# bao1x_peri register map
Vendor: baochip
Registers are 32-bit, read-write, reset 0x0 unless marked. A register's access mark holds for its fields unless they carry their own. Offsets are from the block's base; [hi:lo] are bit positions; {n}, {i} and the like mark numbered series; <NAME> marks a mode.

## UDMA_SPIS_0
Base 0x50112000
Same registers: UDMA_SPIS_1 0x50113000
0x00 REG_RX_SADDR — See `udma_spis_reg.sv <https://github.com/baochip/baochip-1x/blob/main/rtl/modul es/ifsub/rtl/udma_spis_reg.sv>`__
  [11:0] r_rx_startaddr
0x04 REG_RX_SIZE — See `udma_spis_reg.sv <https://github.com/baochip/baochip-1x/blob/main/rtl/modul es/ifsub/rtl/udma_spis_reg.sv>`__
  [15:0] r_rx_size
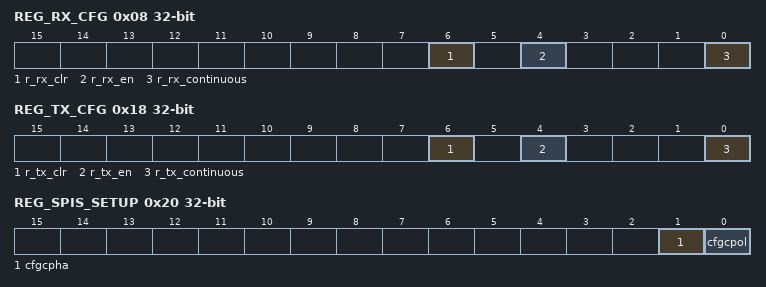
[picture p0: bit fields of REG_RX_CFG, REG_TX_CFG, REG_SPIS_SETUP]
0x08 REG_RX_CFG — See `udma_spis_reg.sv <https://github.com/baochip/baochip-1x/blob/main/rtl/modul es/ifsub/rtl/udma_spis_reg.sv>`__
  [6] r_rx_clr, [4] r_rx_en, [0] r_rx_continuous
0x10 REG_TX_SADDR — See `udma_spis_reg.sv <https://github.com/baochip/baochip-1x/blob/main/rtl/modul es/ifsub/rtl/udma_spis_reg.sv>`__
  [11:0] r_tx_startaddr
0x14 REG_TX_SIZE — See `udma_spis_reg.sv <https://github.com/baochip/baochip-1x/blob/main/rtl/modul es/ifsub/rtl/udma_spis_reg.sv>`__
  [15:0] r_tx_size
0x18 REG_TX_CFG — See `udma_spis_reg.sv <https://github.com/baochip/baochip-1x/blob/main/rtl/modul es/ifsub/rtl/udma_spis_reg.sv>`__
  [6] r_tx_clr, [4] r_tx_en, [0] r_tx_continuous
0x20 REG_SPIS_SETUP — See `udma_spis_reg.sv <https://github.com/baochip/baochip-1x/blob/main/rtl/modul es/ifsub/rtl/udma_spis_reg.sv>`__
  [1] cfgcpha, [0] cfgcpol
0x24 REG_SEOT_CNT — See `udma_spis_reg.sv <https://github.com/baochip/baochip-1x/blob/main/rtl/modul es/ifsub/rtl/udma_spis_reg.sv>`__
  [15:0] sr_seot_cnt
0x28 REG_SPIS_IRQ_EN — See `udma_spis_reg.sv <https://github.com/baochip/baochip-1x/blob/main/rtl/modul es/ifsub/rtl/udma_spis_reg.sv>`__
  [0] seot_irq_en
0x2C REG_SPIS_RXCNT — See `udma_spis_reg.sv <https://github.com/baochip/baochip-1x/blob/main/rtl/modul es/ifsub/rtl/udma_spis_reg.sv>`__
  [15:0] cfgrxcnt
0x30 REG_SPIS_TXCNT — See `udma_spis_reg.sv <https://github.com/baochip/baochip-1x/blob/main/rtl/modul es/ifsub/rtl/udma_spis_reg.sv>`__
  [15:0] cfgtxcnt
0x34 REG_SPIS_DMCNT — See `udma_spis_reg.sv <https://github.com/baochip/baochip-1x/blob/main/rtl/modul es/ifsub/rtl/udma_spis_reg.sv>`__
  [15:0] cfgdmcnt

## UDMA_ADC
Base 0x50114000
0x00 REG_RX_SADDR — See `udma_adc_ts_reg_if.sv <https://github.com/baochip/baochip-1x/blob/main/rtl/ modules/ifsub/rtl/udma_adc_ts_reg_if.sv>`__
  [11:0] r_rx_startaddr
0x04 REG_RX_SIZE — See `udma_adc_ts_reg_if.sv <https://github.com/baochip/baochip-1x/blob/main/rtl/ modules/ifsub/rtl/udma_adc_ts_reg_if.sv>`__
  [15:0] r_rx_size
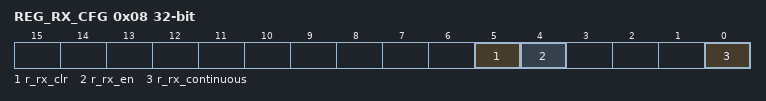
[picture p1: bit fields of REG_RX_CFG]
0x08 REG_RX_CFG — See `udma_adc_ts_reg_if.sv <https://github.com/baochip/baochip-1x/blob/main/rtl/ modules/ifsub/rtl/udma_adc_ts_reg_if.sv>`__
  [5] r_rx_clr, [4] r_rx_en, [0] r_rx_continuous
0x10 REG_CR_ADC — See `udma_adc_ts_reg_if.sv <https://github.com/baochip/baochip-1x/blob/main/rtl/ modules/ifsub/rtl/udma_adc_ts_reg_if.sv>`__
  [27:0] cr_adc

## BIO_FIFO0
Base 0x50129000
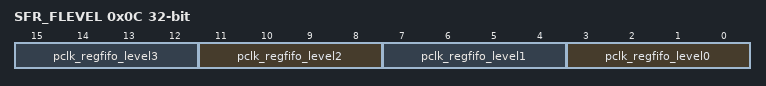
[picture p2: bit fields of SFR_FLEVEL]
0x0C SFR_FLEVEL — See `bio_bdma.sv#L492 <https://github.com/baochip/baochip-1x/blob/main/rtl/modul es/bio_bdma/rtl/bio_bdma.sv#L492>`__ (line numbers are approximate)
  [4n+3:4n] pclk_regfifo_level{n} (n=0..3) — pclk_regfifo_level[{n}] read only status register
0x10 SFR_TXF0 — See `bio_bdma.sv#L493 <https://github.com/baochip/baochip-1x/blob/main/rtl/modul es/bio_bdma/rtl/bio_bdma.sv#L493>`__ (line numbers are approximate)
  [31:0] fdin — fdin read/write control register
0x20 SFR_RXF0 — See `bio_bdma.sv#L497 <https://github.com/baochip/baochip-1x/blob/main/rtl/modul es/bio_bdma/rtl/bio_bdma.sv#L497>`__ (line numbers are approximate)
  [31:0] fdout — fdout read only status register
0x38 SFR_EVENT_SET — See `bio_bdma.sv#L504 <https://github.com/baochip/baochip-1x/blob/main/rtl/modul es/bio_bdma/rtl/bio_bdma.sv#L504>`__ (line numbers are approximate)
  [23:0] sfr_event_set — sfr_event_set read/write control register
0x3C SFR_EVENT_CLR — See `bio_bdma.sv#L505 <https://github.com/baochip/baochip-1x/blob/main/rtl/modul es/bio_bdma/rtl/bio_bdma.sv#L505>`__ (line numbers are approximate)
  [23:0] sfr_event_clr — sfr_event_clr read/write control register
0x40 SFR_EVENT_STATUS — See `bio_bdma.sv#L506 <https://github.com/baochip/baochip-1x/blob/main/rtl/modul es/bio_bdma/rtl/bio_bdma.sv#L506>`__ (line numbers are approximate)
  [31:0] sfr_event_status — sfr_event_status read only status register
